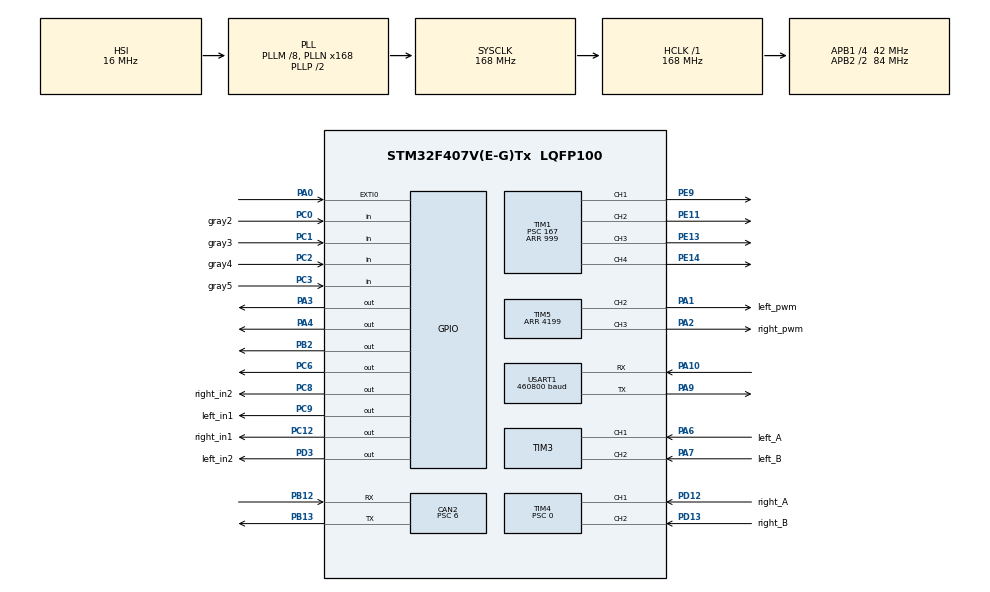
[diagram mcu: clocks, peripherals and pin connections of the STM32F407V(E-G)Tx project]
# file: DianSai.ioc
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CAN2.ABOM=ENABLE
CAN2.BS1=CAN_BS1_11TQ
CAN2.BS2=CAN_BS2_2TQ
CAN2.CalculateBaudRate=500000
CAN2.CalculateTimeBit=2000
CAN2.CalculateTimeQuantum=142.85714285714286
CAN2.NART=ENABLE
CAN2.Prescaler=6
CAN2.TTCM=DISABLE
Dma.Request0=USART1_RX
Dma.USART1_RX.0.Direction=DMA_PERIPH_TO_MEMORY
Dma.USART1_RX.0.FIFOMode=DMA_FIFOMODE_DISABLE
Dma.USART1_RX.0.Instance=DMA2_Stream2
Dma.USART1_RX.0.MemDataAlignment=DMA_MDATAALIGN_BYTE
Dma.USART1_RX.0.MemInc=DMA_MINC_ENABLE
Dma.USART1_RX.0.Mode=DMA_CIRCULAR
Dma.USART1_RX.0.PeriphDataAlignment=DMA_PDATAALIGN_BYTE
Dma.USART1_RX.0.PeriphInc=DMA_PINC_DISABLE
Dma.USART1_RX.0.Priority=DMA_PRIORITY_LOW
FREERTOS.Tasks01=defaultTask,24,128,StartDefaultTask,Default,NULL,Dynamic,NULL,NULL
Mcu.Family=STM32F4
Mcu.Name=STM32F407V(E-G)Tx
Mcu.Package=LQFP100
NVIC.CAN2_RX0_IRQn=true\:5\:0\:false\:false\:true\:true\:true\:true\:true
NVIC.CAN2_RX1_IRQn=true\:5\:0\:false\:false\:true\:true\:true\:true\:true
NVIC.DMA2_Stream2_IRQn=true\:5\:0\:false\:false\:true\:true\:false\:true\:true
NVIC.EXTI0_IRQn=true\:5\:0\:false\:false\:true\:true\:true\:true\:true
NVIC.PriorityGroup=NVIC_PRIORITYGROUP_4
NVIC.TIM2_IRQn=true\:15\:0\:false\:false\:true\:false\:false\:true\:true
NVIC.TimeBase=TIM2_IRQn
NVIC.TimeBaseIP=TIM2
NVIC.USART1_IRQn=true\:5\:0\:false\:false\:true\:true\:true\:true\:true
PA0-WKUP.GPIO_ModeDefaultEXTI=GPIO_MODE_IT_RISING_FALLING
PA0-WKUP.GPIO_PuPd=GPIO_PULLDOWN
PA0-WKUP.Signal=GPXTI0
PA1.GPIO_Label=left_pwm
PA1.Signal=S_TIM5_CH2
PA10.Mode=Asynchronous
PA10.Signal=USART1_RX
PA13.Mode=Serial_Wire
PA13.Signal=SYS_JTMS-SWDIO
PA14.Mode=Serial_Wire
PA14.Signal=SYS_JTCK-SWCLK
PA2.GPIO_Label=right_pwm
PA2.Signal=S_TIM5_CH3
PA3.GPIO_PuPd=GPIO_PULLDOWN
PA3.Signal=GPIO_Output
PA4.GPIO_PuPd=GPIO_PULLDOWN
PA4.Signal=GPIO_Output
PA6.GPIO_Label=left_A
PA6.Signal=S_TIM3_CH1
PA7.GPIO_Label=left_B
PA7.Signal=S_TIM3_CH2
PA9.Mode=Asynchronous
PA9.Signal=USART1_TX
PB12.Mode=CAN_Activate
PB12.Signal=CAN2_RX
PB13.Mode=CAN_Activate
PB13.Signal=CAN2_TX
PB2.Signal=GPIO_Output
PC0.GPIO_Label=gray2
PC0.GPIO_PuPd=GPIO_PULLDOWN
PC0.Signal=GPIO_Input
PC1.GPIO_Label=gray3
PC1.GPIO_PuPd=GPIO_PULLDOWN
PC1.Signal=GPIO_Input
PC12.GPIO_Label=right_in1
PC12.GPIO_PuPd=GPIO_PULLDOWN
PC12.Signal=GPIO_Output
PC2.GPIO_Label=gray4
PC2.GPIO_PuPd=GPIO_PULLDOWN
PC2.Signal=GPIO_Input
PC3.GPIO_Label=gray5
PC3.GPIO_PuPd=GPIO_PULLDOWN
PC3.Signal=GPIO_Input
PC6.GPIO_ModeDefaultOutputPP=GPIO_MODE_OUTPUT_PP
PC6.GPIO_PuPd=GPIO_PULLDOWN
PC6.GPIO_Speed=GPIO_SPEED_FREQ_HIGH
PC6.PinState=GPIO_PIN_SET
PC6.Signal=GPIO_Output
PC8.GPIO_Label=right_in2
PC8.GPIO_PuPd=GPIO_PULLDOWN
PC8.Signal=GPIO_Output
PC9.GPIO_Label=left_in1
PC9.GPIO_PuPd=GPIO_PULLDOWN
PC9.Signal=GPIO_Output
PD12.GPIO_Label=right_A
PD12.Signal=S_TIM4_CH1
PD13.GPIO_Label=right_B
PD13.Signal=S_TIM4_CH2
PD3.GPIO_Label=left_in2
PD3.GPIO_PuPd=GPIO_PULLDOWN
PD3.Signal=GPIO_Output
PE11.Signal=S_TIM1_CH2
PE13.Signal=S_TIM1_CH3
PE14.Signal=S_TIM1_CH4
PE9.Signal=S_TIM1_CH1
ProjectManager.HeapSize=0x1000
ProjectManager.StackSize=0x800
ProjectManager.TargetToolchain=MDK-ARM V5.32
RCC.48MHZClocksFreq_Value=84000000
RCC.AHBFreq_Value=168000000
RCC.APB1CLKDivider=RCC_HCLK_DIV4
RCC.APB1Freq_Value=42000000
RCC.APB1TimFreq_Value=84000000
RCC.APB2CLKDivider=RCC_HCLK_DIV2
RCC.APB2Freq_Value=84000000
RCC.APB2TimFreq_Value=168000000
RCC.CortexFreq_Value=168000000
RCC.HCLKFreq_Value=168000000
RCC.HSE_VALUE=25000000
RCC.HSI_VALUE=16000000
RCC.LSE_VALUE=32768
RCC.PLLM=8
RCC.PLLN=168
RCC.SYSCLKFreq_VALUE=168000000
RCC.SYSCLKSource=RCC_SYSCLKSOURCE_PLLCLK
RCC.VCOOutputFreq_Value=336000000
SH.S_TIM1_CH1.0=TIM1_CH1,PWM Generation1 CH1
SH.S_TIM1_CH2.0=TIM1_CH2,PWM Generation2 CH2
SH.S_TIM1_CH3.0=TIM1_CH3,PWM Generation3 CH3
SH.S_TIM1_CH4.0=TIM1_CH4,PWM Generation4 CH4
SH.S_TIM3_CH1.0=TIM3_CH1,Encoder_Interface
SH.S_TIM3_CH2.0=TIM3_CH2,Encoder_Interface
SH.S_TIM4_CH1.0=TIM4_CH1,Encoder_Interface
SH.S_TIM4_CH2.0=TIM4_CH2,Encoder_Interface
SH.S_TIM5_CH2.0=TIM5_CH2,PWM Generation2 CH2
SH.S_TIM5_CH3.0=TIM5_CH3,PWM Generation3 CH3
TIM1.AutoReloadPreload=TIM_AUTORELOAD_PRELOAD_ENABLE
TIM1.Channel-PWM\ Generation1\ CH1=TIM_CHANNEL_1
TIM1.Channel-PWM\ Generation2\ CH2=TIM_CHANNEL_2
TIM1.Channel-PWM\ Generation3\ CH3=TIM_CHANNEL_3
TIM1.Channel-PWM\ Generation4\ CH4=TIM_CHANNEL_4
TIM1.Period=999
TIM1.Prescaler=167
TIM3.EncoderMode=TIM_ENCODERMODE_TI12
TIM3.IC1Filter=4
TIM3.IC2Filter=4
TIM4.AutoReloadPreload=TIM_AUTORELOAD_PRELOAD_DISABLE
TIM4.EncoderMode=TIM_ENCODERMODE_TI12
TIM4.IC1Filter=4
TIM4.IC2Filter=4
TIM4.Period=65535
TIM4.Prescaler=0
TIM5.AutoReloadPreload=TIM_AUTORELOAD_PRELOAD_ENABLE
TIM5.Channel-PWM\ Generation2\ CH2=TIM_CHANNEL_2
TIM5.Channel-PWM\ Generation3\ CH3=TIM_CHANNEL_3
TIM5.Period=4199
USART1.BaudRate=460800
USART1.VirtualMode=VM_ASYNC
VP_FREERTOS_VS_CMSIS_V2.Mode=CMSIS_V2
VP_SYS_VS_tim2.Mode=TIM2
VP_TIM1_VS_ClockSourceINT.Mode=Internal
VP_TIM5_VS_ClockSourceINT.Mode=Internal
board=custom

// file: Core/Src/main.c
/* USER CODE BEGIN Header */
/**
  ******************************************************************************
  * @file           : main.c
  * @brief          : Main program body
  ******************************************************************************
  * @attention
  *
  * Copyright (c) 2026 STMicroelectronics.
  * All rights reserved.
  *
  * This software is licensed under terms that can be found in the LICENSE file
  * in the root directory of this software component.
  * If no LICENSE file comes with this software, it is provided AS-IS.
  *
  ******************************************************************************
  */
/* USER CODE END Header */
#include "main.h"
#include "cmsis_os.h"
#include "can.h"
#include "dma.h"
#include "tim.h"
#include "usart.h"
#include "gpio.h"

/* USER CODE BEGIN Includes */
#include "bsp_tim.h"
/* USER CODE END Includes */

void SystemClock_Config(void);
void MX_FREERTOS_Init(void);

int main(void)
{

  /* MCU Configuration--------------------------------------------------------*/

  /* Reset of all peripherals, Initializes the Flash interface and the Systick. */
  HAL_Init();

  /* Configure the system clock */
  SystemClock_Config();

  /* Initialize all configured peripherals */
  MX_GPIO_Init();
  MX_DMA_Init();
  MX_USART1_UART_Init();
  MX_TIM1_Init();
  MX_TIM3_Init();
  MX_TIM4_Init();
  MX_TIM5_Init();
  MX_CAN2_Init();

  /* Init scheduler */
  osKernelInitialize();  /* Call init function for freertos objects (in cmsis_os2.c) */
  MX_FREERTOS_Init();

  /* Start scheduler */
  osKernelStart();

  /* We should never get here as control is now taken by the scheduler */

  /* Infinite loop */
  while (1)
  {

  }
}

void SystemClock_Config(void)
{
  RCC_OscInitTypeDef RCC_OscInitStruct = {0};
  RCC_ClkInitTypeDef RCC_ClkInitStruct = {0};

  /** Configure the main internal regulator output voltage
  */
  __HAL_RCC_PWR_CLK_ENABLE();
  __HAL_PWR_VOLTAGESCALING_CONFIG(PWR_REGULATOR_VOLTAGE_SCALE1);

  /** Initializes the RCC Oscillators according to the specified parameters
  * in the RCC_OscInitTypeDef structure.
  */
  RCC_OscInitStruct.OscillatorType = RCC_OSCILLATORTYPE_HSI;
  RCC_OscInitStruct.HSIState = RCC_HSI_ON;
  RCC_OscInitStruct.HSICalibrationValue = RCC_HSICALIBRATION_DEFAULT;
  RCC_OscInitStruct.PLL.PLLState = RCC_PLL_ON;
  RCC_OscInitStruct.PLL.PLLSource = RCC_PLLSOURCE_HSI;
  RCC_OscInitStruct.PLL.PLLM = 8;
  RCC_OscInitStruct.PLL.PLLN = 168;
  RCC_OscInitStruct.PLL.PLLP = RCC_PLLP_DIV2;
  RCC_OscInitStruct.PLL.PLLQ = 4;
  if (HAL_RCC_OscConfig(&RCC_OscInitStruct) != HAL_OK)
  {
    Error_Handler();
  }

  /** Initializes the CPU, AHB and APB buses clocks
  */
  RCC_ClkInitStruct.ClockType = RCC_CLOCKTYPE_HCLK|RCC_CLOCKTYPE_SYSCLK
                              |RCC_CLOCKTYPE_PCLK1|RCC_CLOCKTYPE_PCLK2;
  RCC_ClkInitStruct.SYSCLKSource = RCC_SYSCLKSOURCE_PLLCLK;
  RCC_ClkInitStruct.AHBCLKDivider = RCC_SYSCLK_DIV1;
  RCC_ClkInitStruct.APB1CLKDivider = RCC_HCLK_DIV4;
  RCC_ClkInitStruct.APB2CLKDivider = RCC_HCLK_DIV2;

  if (HAL_RCC_ClockConfig(&RCC_ClkInitStruct, FLASH_LATENCY_5) != HAL_OK)
  {
    Error_Handler();
  }
}

void HAL_TIM_PeriodElapsedCallback(TIM_HandleTypeDef *htim)
{
  if (htim->Instance == TIM2)
  {
    HAL_IncTick();
  }
  /* USER CODE BEGIN Callback 1 */
  TIMPeriodElapsedCallback(htim);

  /* USER CODE END Callback 1 */
}

void Error_Handler(void)
{
  __disable_irq();
  while (1)
  {
  }
}

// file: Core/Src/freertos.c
/* USER CODE BEGIN Header */
/**
  ******************************************************************************
  * File Name          : freertos.c
  * Description        : Code for freertos applications
  ******************************************************************************
  * @attention
  *
  * Copyright (c) 2026 STMicroelectronics.
  * All rights reserved.
  *
  * This software is licensed under terms that can be found in the LICENSE file
  * in the root directory of this software component.
  * If no LICENSE file comes with this software, it is provided AS-IS.
  *
  ******************************************************************************
  */
/* USER CODE END Header */

#include "FreeRTOS.h"
#include "task.h"
#include "main.h"
#include "cmsis_os.h"

/* USER CODE BEGIN Includes */
#include "robot.h"
/* USER CODE END Includes */

/* Definitions for defaultTask */
osThreadId_t defaultTaskHandle;
const osThreadAttr_t defaultTask_attributes = {
  .name = "defaultTask",
  .stack_size = 128 * 4,
  .priority = (osPriority_t) osPriorityNormal,
};

void StartDefaultTask(void *argument);

void MX_FREERTOS_Init(void); /* (MISRA C 2004 rule 8.1) */

void MX_FREERTOS_Init(void) {
  /* USER CODE BEGIN Init */
  robotInit();
  /* USER CODE END Init */

  /* Create the thread(s) */
  /* creation of defaultTask */
  defaultTaskHandle = osThreadNew(StartDefaultTask, NULL, &defaultTask_attributes);

}

void StartDefaultTask(void *argument)
{
  for(;;)
  {
    osDelay(1);
  }
}
